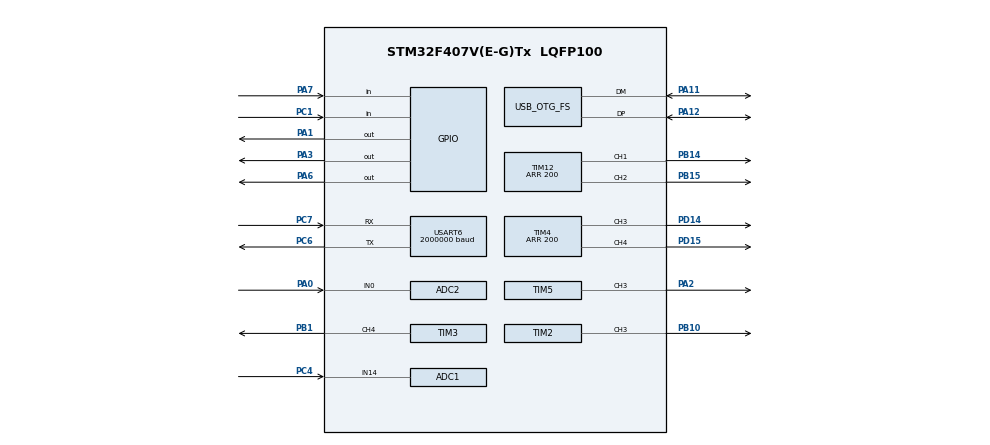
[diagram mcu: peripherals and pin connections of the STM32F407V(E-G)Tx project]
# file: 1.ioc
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ADC1.Channel-0\#ChannelRegularConversion=ADC_CHANNEL_14
ADC1.ClockPrescaler=ADC_CLOCK_SYNC_PCLK_DIV4
ADC1.NbrOfConversionFlag=1
ADC1.Rank-0\#ChannelRegularConversion=1
ADC1.SamplingTime-0\#ChannelRegularConversion=ADC_SAMPLETIME_3CYCLES
ADC1.master=1
ADC2.Channel-0\#ChannelRegularConversion=ADC_CHANNEL_0
ADC2.ClockPrescaler=ADC_CLOCK_SYNC_PCLK_DIV4
ADC2.NbrOfConversionFlag=1
ADC2.Rank-0\#ChannelRegularConversion=1
ADC2.SamplingTime-0\#ChannelRegularConversion=ADC_SAMPLETIME_3CYCLES
Mcu.Family=STM32F4
Mcu.Name=STM32F407V(E-G)Tx
Mcu.Package=LQFP100
NVIC.OTG_FS_IRQn=true\:0\:0\:false\:false\:true\:false
NVIC.PriorityGroup=NVIC_PRIORITYGROUP_4
NVIC.TIM2_IRQn=true\:0\:0\:false\:false\:true\:true
NVIC.TIM3_IRQn=true\:0\:0\:false\:false\:true\:true
PA0-WKUP.Signal=ADCx_IN0
PA1.GPIO_Speed=GPIO_SPEED_FREQ_VERY_HIGH
PA1.Signal=GPIO_Output
PA11.Mode=Device_Only
PA11.Signal=USB_OTG_FS_DM
PA12.Mode=Device_Only
PA12.Signal=USB_OTG_FS_DP
PA2.Signal=S_TIM5_CH3
PA3.GPIO_Speed=GPIO_SPEED_FREQ_VERY_HIGH
PA3.Signal=GPIO_Output
PA6.GPIO_Speed=GPIO_SPEED_FREQ_VERY_HIGH
PA6.Signal=GPIO_Output
PA7.Signal=GPIO_Input
PB1.GPIO_Speed=GPIO_SPEED_FREQ_VERY_HIGH
PB1.Signal=S_TIM3_CH4
PB10.GPIO_Speed=GPIO_SPEED_FREQ_VERY_HIGH
PB10.Signal=S_TIM2_CH3
PB14.Signal=S_TIM12_CH1
PB15.Signal=S_TIM12_CH2
PC1.Signal=GPIO_Input
PC4.Signal=ADCx_IN14
PC6.Mode=Asynchronous
PC6.Signal=USART6_TX
PC7.Mode=Asynchronous
PC7.Signal=USART6_RX
PD14.GPIO_Speed=GPIO_SPEED_FREQ_VERY_HIGH
PD14.Signal=S_TIM4_CH3
PD15.GPIO_Speed=GPIO_SPEED_FREQ_VERY_HIGH
PD15.Signal=S_TIM4_CH4
PH0-OSC_IN.Mode=HSE-External-Oscillator
PH0-OSC_IN.Signal=RCC_OSC_IN
PH1-OSC_OUT.Mode=HSE-External-Oscillator
PH1-OSC_OUT.Signal=RCC_OSC_OUT
ProjectManager.HeapSize=0x200
ProjectManager.StackSize=0x400
ProjectManager.TargetToolchain=MDK-ARM V5
RCC.48MHZClocksFreq_Value=48000000
RCC.AHBFreq_Value=168000000
RCC.APB1CLKDivider=RCC_HCLK_DIV4
RCC.APB1Freq_Value=42000000
RCC.APB1TimFreq_Value=84000000
RCC.APB2CLKDivider=RCC_HCLK_DIV2
RCC.APB2Freq_Value=84000000
RCC.APB2TimFreq_Value=168000000
RCC.CortexFreq_Value=168000000
RCC.HCLKFreq_Value=168000000
RCC.HSE_VALUE=8000000
RCC.HSI_VALUE=16000000
RCC.LSE_VALUE=32768
RCC.PLLM=4
RCC.PLLN=168
RCC.PLLQ=7
RCC.SYSCLKFreq_VALUE=168000000
RCC.SYSCLKSource=RCC_SYSCLKSOURCE_PLLCLK
RCC.VCOOutputFreq_Value=336000000
SH.ADCx_IN0.0=ADC2_IN0,IN0
SH.ADCx_IN14.0=ADC1_IN14,IN14
SH.S_TIM12_CH1.0=TIM12_CH1,PWM Generation1 CH1
SH.S_TIM12_CH2.0=TIM12_CH2,PWM Generation2 CH2
SH.S_TIM2_CH3.0=TIM2_CH3,PWM Generation3 CH3
SH.S_TIM3_CH4.0=TIM3_CH4,PWM Generation4 CH4
SH.S_TIM4_CH3.0=TIM4_CH3,PWM Generation3 CH3
SH.S_TIM4_CH4.0=TIM4_CH4,PWM Generation4 CH4
SH.S_TIM5_CH3.0=TIM5_CH3,PWM Generation3 CH3
TIM12.Channel-PWM\ Generation1\ CH1=TIM_CHANNEL_1
TIM12.Channel-PWM\ Generation2\ CH2=TIM_CHANNEL_2
TIM12.Period=200
TIM12.Pulse-PWM\ Generation1\ CH1=100
TIM12.Pulse-PWM\ Generation2\ CH2=100
TIM2.Channel-PWM\ Generation3\ CH3=TIM_CHANNEL_3
TIM2.Period=1000
TIM2.Prescaler=0
TIM2.Pulse-PWM\ Generation3\ CH3=200
TIM3.Channel-PWM\ Generation4\ CH4=TIM_CHANNEL_4
TIM3.Period=1000
TIM3.Pulse-PWM\ Generation4\ CH4=900
TIM4.Channel-PWM\ Generation3\ CH3=TIM_CHANNEL_3
TIM4.Channel-PWM\ Generation4\ CH4=TIM_CHANNEL_4
TIM4.OCFastMode_PWM-PWM\ Generation3\ CH3=TIM_OCFAST_ENABLE
TIM4.OCFastMode_PWM-PWM\ Generation4\ CH4=TIM_OCFAST_ENABLE
TIM4.Period=200
TIM4.Pulse-PWM\ Generation3\ CH3=0
TIM4.Pulse-PWM\ Generation4\ CH4=0
TIM4.TIM_MasterOutputTrigger=TIM_TRGO_ENABLE
TIM5.Channel-PWM\ Generation3\ CH3=TIM_CHANNEL_3
TIM5.Period=90
TIM5.Pulse-PWM\ Generation3\ CH3=45
TIM5.TIM_MasterOutputTrigger=TIM_TRGO_ENABLE
USART6.BaudRate=2000000
USART6.VirtualMode=VM_ASYNC
USB_DEVICE.CLASS_NAME_FS=CDC
USB_DEVICE.CLASS_NAME_HS=CDC
USB_DEVICE.VirtualMode-CDC_FS=Cdc
USB_DEVICE.VirtualMode-CDC_HS=Cdc
USB_DEVICE.VirtualModeFS=Cdc_FS
USB_DEVICE.VirtualModeHS=Cdc_HS
USB_OTG_FS.VirtualMode=Device_Only
VP_USB_DEVICE_VS_USB_DEVICE_CDC_FS.Mode=CDC_FS
board=1

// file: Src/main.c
/**
  ******************************************************************************
  * @file           : main.c
  * @brief          : Main program body
  ******************************************************************************
  * This notice applies to any and all portions of this file
  * that are not between comment pairs USER CODE BEGIN and
  * USER CODE END. Other portions of this file, whether
  * inserted by the user or by software development tools
  * are owned by their respective copyright owners.
  *
  * Copyright (c) 2018 STMicroelectronics International N.V.
  * All rights reserved.
  *
  * Redistribution and use in source and binary forms, with or without
  * modification, are permitted, provided that the following conditions are met:
  *
  * 1. Redistribution of source code must retain the above copyright notice,
  *    this list of conditions and the following disclaimer.
  * 2. Redistributions in binary form must reproduce the above copyright notice,
  *    this list of conditions and the following disclaimer in the documentation
  *    and/or other materials provided with the distribution.
  * 3. Neither the name of STMicroelectronics nor the names of other
  *    contributors to this software may be used to endorse or promote products
  *    derived from this software without specific written permission.
  * 4. This software, including modifications and/or derivative works of this
  *    software, must execute solely and exclusively on microcontroller or
  *    microprocessor devices manufactured by or for STMicroelectronics.
  * 5. Redistribution and use of this software other than as permitted under
  *    this license is void and will automatically terminate your rights under
  *    this license.
  *
  * THIS SOFTWARE IS PROVIDED BY STMICROELECTRONICS AND CONTRIBUTORS "AS IS"
  * AND ANY EXPRESS, IMPLIED OR STATUTORY WARRANTIES, INCLUDING, BUT NOT
  * LIMITED TO, THE IMPLIED WARRANTIES OF MERCHANTABILITY, FITNESS FOR A
  * PARTICULAR PURPOSE AND NON-INFRINGEMENT OF THIRD PARTY INTELLECTUAL PROPERTY
  * RIGHTS ARE DISCLAIMED TO THE FULLEST EXTENT PERMITTED BY LAW. IN NO EVENT
  * SHALL STMICROELECTRONICS OR CONTRIBUTORS BE LIABLE FOR ANY DIRECT, INDIRECT,
  * INCIDENTAL, SPECIAL, EXEMPLARY, OR CONSEQUENTIAL DAMAGES (INCLUDING, BUT NOT
  * LIMITED TO, PROCUREMENT OF SUBSTITUTE GOODS OR SERVICES; LOSS OF USE, DATA,
  * OR PROFITS; OR BUSINESS INTERRUPTION) HOWEVER CAUSED AND ON ANY THEORY OF
  * LIABILITY, WHETHER IN CONTRACT, STRICT LIABILITY, OR TORT (INCLUDING
  * NEGLIGENCE OR OTHERWISE) ARISING IN ANY WAY OUT OF THE USE OF THIS SOFTWARE,
  * EVEN IF ADVISED OF THE POSSIBILITY OF SUCH DAMAGE.
  *
  ******************************************************************************
  */
#include "main.h"
#include "stdio.h"
#include "stm32f4xx_hal.h"
#include "usb_device.h"
#include "TIM_INIT.h"
//#define CDC_DATA_HS_MAX_PACKET_SIZE                 256  /* Endpoint IN & OUT Packet size */
/* USER CODE BEGIN Includes */
//TIM_HandleTypeDef htim4;
/* USER CODE END Includes */

TIM_HandleTypeDef htim5;
TIM_HandleTypeDef htim12;

/* USER CODE BEGIN PV */
/* Private variables ---------------------------------------------------------*/

/* USER CODE END PV */

void SystemClock_Config(void);
static void MX_GPIO_Init(void);
static void MX_TIM2_Init(void);
static void MX_ADC1_Init(void);
static void MX_ADC2_Init(void);
static void MX_USART6_UART_Init(void);
static void MX_TIM3_Init(void);
static void MX_TIM4_Init(void);
static void MX_TIM12_Init(void);
static void MX_TIM5_Init(void);
//static void init_EXTI(void);

void HAL_TIM_MspPostInit(TIM_HandleTypeDef *htim);
//void CDC_Transmit_FS ();

/* USER CODE BEGIN PFP */
/* Private function prototypes -----------------------------------------------*/

/* USER CODE END PFP */

/* USER CODE BEGIN 0 */

/* USER CODE BEGIN 0 */
/* USER CODE END 0 */

int main(void)
{

  /* MCU Configuration----------------------------------------------------------*/

  /* Reset of all peripherals, Initializes the Flash interface and the Systick. */
  HAL_Init();

  /* Configure the system clock */
  SystemClock_Config();

  /* Initialize all configured peripherals */
  MX_GPIO_Init();
  MX_TIM2_Init();
  MX_ADC1_Init();
  MX_ADC2_Init();
  MX_USB_DEVICE_Init();
  MX_USART6_UART_Init();
  MX_TIM3_Init();
  MX_TIM4_Init();
  MX_TIM12_Init();
  MX_TIM5_Init();
	//init_EXTI();
  /* USER CODE BEGIN 2 */
	//TIM4->CR1 &= ~TIM_CR1_CEN; tim dis
	TIM2->CR1  |= TIM_CR1_CEN;
	TIM3->CR1  |= TIM_CR1_CEN;
	TIM4->CR1  |= TIM_CR1_CEN;
	TIM5->CR1  |= TIM_CR1_CEN;
	TIM12->CR1 |= TIM_CR1_CEN;
  /* USER CODE END 2 */
		char str_tx[30];
		sprintf(str_tx,"IIAA  ROBOTAU!!!\r\n");

  /* Infinite loop */
  /* USER CODE BEGIN WHILE */

  while (1)
  {
			CDC_Transmit_FS((unsigned char*)str_tx, strlen(str_tx));
			HAL_Delay(500);
			GPIOA->ODR = 0x0007;
			GPIOA->ODR = 0x0000;
			HAL_GPIO_TogglePin(GPIOE, GPIO_PIN_2);
		/* USER CODE BEGIN 3 */
	//GPIOA->BSRR = GPIO_PIN_1;
	//GPIOA->BSRR = !GPIO_PIN_1;
  /* USER CODE END WHILE */

  /* USER CODE BEGIN 3 */
	//GPIOE->BSRR = GPIO_PIN_2;
	//GPIOA->BSRR = !GPIO_PIN_1;
  /* USER CODE END WHILE */

  /* USER CODE BEGIN 3 */
	//GPIOA->BSRR = GPIO_PIN_1;
	//GPIOA->BSRR = !GPIO_PIN_1;
  /* USER CODE END WHILE */

	//GPIOA->ODR = 0x0007;
//GPIOA->ODR = 0x0000;

  }
  /* USER CODE END 3 */

}

/** Configure pins as
        * Analog
        * Input
        * Output
        * EVENT_OUT
        * EXTI
*/
static void MX_GPIO_Init(void)
{

  LL_GPIO_InitTypeDef GPIO_InitStruct;

  /* GPIO Ports Clock Enable */
  LL_AHB1_GRP1_EnableClock(LL_AHB1_GRP1_PERIPH_GPIOH);
  LL_AHB1_GRP1_EnableClock(LL_AHB1_GRP1_PERIPH_GPIOC);
  LL_AHB1_GRP1_EnableClock(LL_AHB1_GRP1_PERIPH_GPIOA);
  LL_AHB1_GRP1_EnableClock(LL_AHB1_GRP1_PERIPH_GPIOB);
  LL_AHB1_GRP1_EnableClock(LL_AHB1_GRP1_PERIPH_GPIOD);
	LL_AHB1_GRP1_EnableClock(LL_AHB1_GRP1_PERIPH_GPIOE);

  /**/
  LL_GPIO_ResetOutputPin(GPIOA, LL_GPIO_PIN_1|LL_GPIO_PIN_3|LL_GPIO_PIN_6);

  /**/
  GPIO_InitStruct.Pin = LL_GPIO_PIN_1;
  GPIO_InitStruct.Mode = LL_GPIO_MODE_INPUT;
  GPIO_InitStruct.Pull = LL_GPIO_PULL_NO;
  LL_GPIO_Init(GPIOC, &GPIO_InitStruct);

  /**/
  GPIO_InitStruct.Pin = LL_GPIO_PIN_1|LL_GPIO_PIN_3|LL_GPIO_PIN_6;
  GPIO_InitStruct.Mode = LL_GPIO_MODE_OUTPUT;
  GPIO_InitStruct.Speed = LL_GPIO_SPEED_FREQ_VERY_HIGH;
  GPIO_InitStruct.OutputType = LL_GPIO_OUTPUT_PUSHPULL;
  GPIO_InitStruct.Pull = LL_GPIO_PULL_NO;
  LL_GPIO_Init(GPIOA, &GPIO_InitStruct);

	GPIO_InitStruct.Pin = LL_GPIO_PIN_2;
  GPIO_InitStruct.Mode = LL_GPIO_MODE_OUTPUT;
  GPIO_InitStruct.Speed = LL_GPIO_SPEED_FREQ_VERY_HIGH;
  GPIO_InitStruct.OutputType = LL_GPIO_OUTPUT_PUSHPULL;
  GPIO_InitStruct.Pull = LL_GPIO_PULL_NO;
  LL_GPIO_Init(GPIOE, &GPIO_InitStruct);

  /**/

}

void _Error_Handler(char *file, int line)
{
  while(1)
  {
  }
}

/************************ (C) COPYRIGHT STMicroelectronics *****END OF FILE****/
